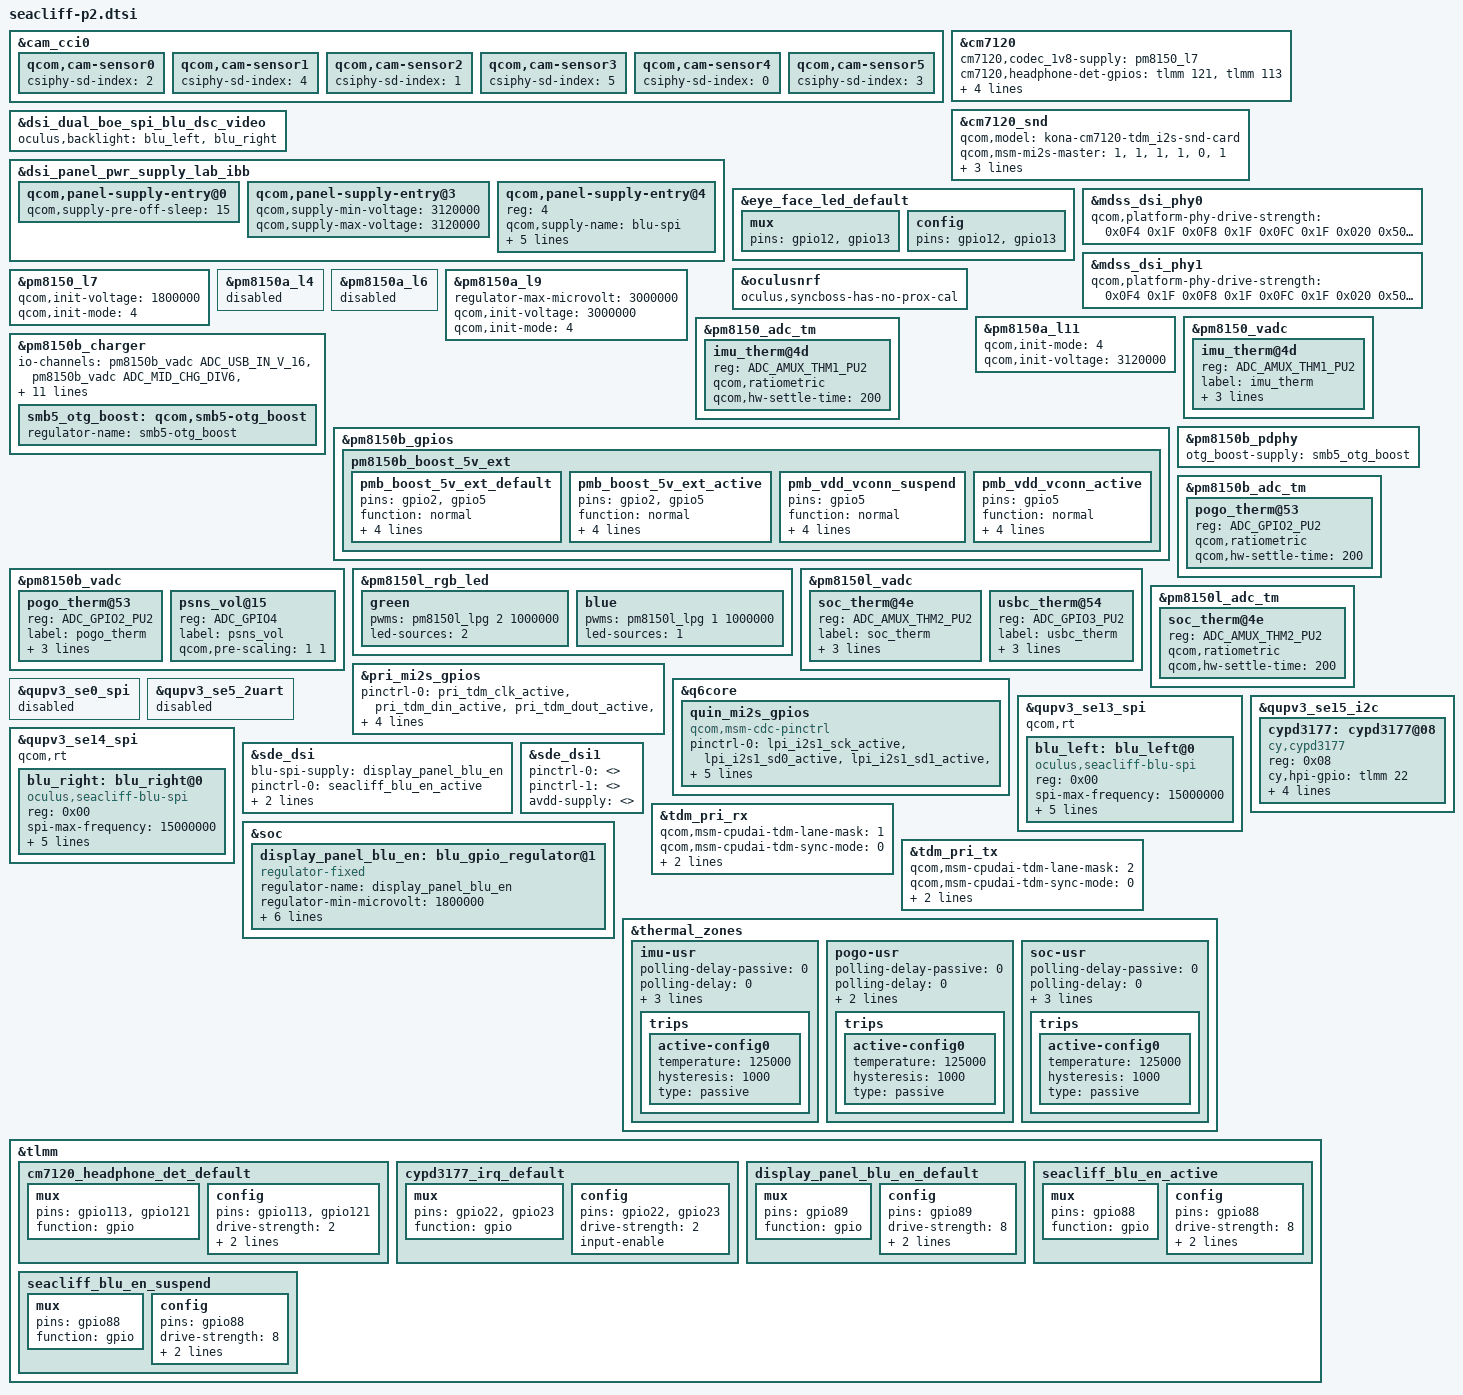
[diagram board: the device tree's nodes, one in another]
#include <dt-bindings/clock/qcom,gcc-kona.h>
#include <dt-bindings/clock/qcom,camcc-kona.h>
#include <dt-bindings/clock/qcom,rpmh.h>
#include <dt-bindings/interrupt-controller/arm-gic.h>

#include "seacliff-pop.dtsi"
#include "seacliff-bcmdhd.dtsi"
#include "seacliff-eye-face-led.dtsi"
#include "seacliff-safetyboss.dtsi"

&cam_cci0 {
	qcom,cam-sensor0 {
		csiphy-sd-index = <2>;
	};
	qcom,cam-sensor1 {
		csiphy-sd-index = <4>;
	};
	qcom,cam-sensor2 {
		csiphy-sd-index = <1>;
	};
	qcom,cam-sensor3 {
		csiphy-sd-index = <5>;
	};
	qcom,cam-sensor4 {
		csiphy-sd-index = <0>;
	};
	qcom,cam-sensor5 {
		csiphy-sd-index = <3>;
	};
};

&cm7120 {
	cm7120,codec_1v8-supply = <&pm8150_l7>;
	cm7120,headphone-det-gpios = <&tlmm 121 0
				   &tlmm 113 0>;
	cm7120,firmware-name = "CM7120_TDM_I2S.bin";
	pinctrl-0 = <&cm7120_codec_ldo_en_default
		&cm7120_codec_reset_default
		&cm7120_headphone_det_default>;
};

&cm7120_snd {
	qcom,model = "kona-cm7120-tdm_i2s-snd-card";
	qcom,msm-mi2s-master = <1>, <1>, <1>, <1>, <0>, <1>;
	qcom,quin-mi2s-gpios = <&quin_mi2s_gpios>;
	qcom,tdm-audio-intf = <1>;
	qcom,tdm-max-slots = <4>;
};

&dsi_dual_boe_spi_blu_dsc_video {
	oculus,backlight = <&blu_left &blu_right>;
};

&dsi_panel_pwr_supply_lab_ibb {
	qcom,panel-supply-entry@0 {
		qcom,supply-pre-off-sleep = <15>;
	};

	qcom,panel-supply-entry@3 {
		qcom,supply-min-voltage = <3120000>;
		qcom,supply-max-voltage = <3120000>;
	};

	qcom,panel-supply-entry@4 {
		reg = <4>;
		qcom,supply-name = "blu-spi";
		qcom,supply-min-voltage = <1800000>;
		qcom,supply-max-voltage = <1800000>;
		qcom,supply-enable-load = <62000>;
		qcom,supply-disable-load = <0>;
		qcom,supply-pre-on-sleep = <10>;
	};
};

&eye_face_led_default {
	mux {
		pins = "gpio12", "gpio13";
	};

	config {
		pins = "gpio12", "gpio13";
	};
};

&mdss_dsi_phy0 {
	qcom,platform-phy-drive-strength = <0x0F4 0x1F
		0x0F8 0x1F
		0x0FC 0x1F
		0x020 0x50
		0x110 0x55>;
};

&mdss_dsi_phy1 {
	qcom,platform-phy-drive-strength = <0x0F4 0x1F
		0x0F8 0x1F
		0x0FC 0x1F
		0x020 0x50
		0x110 0x55>;
};

&oculusnrf {
	oculus,syncboss-has-no-prox-cal;
};

&pm8150_l7 {
	qcom,init-voltage = <1800000>;
	qcom,init-mode = <4>; /* RPMH_REGULATOR_MODE_HPM */
};

&pm8150a_l4 {
	status = "disabled";
};

&pm8150a_l6 {
	status = "disabled";
};

&pm8150a_l9 {
	regulator-max-microvolt = <3000000>;
	qcom,init-voltage = <3000000>;
	qcom,init-mode = <4>; /* RPMH_REGULATOR_MODE_HPM */
};

&pm8150a_l11 {
	qcom,init-mode = <4>; /* RPMH_REGULATOR_MODE_HPM */
	qcom,init-voltage = <3120000>;
};

&pm8150_vadc {
	imu_therm@4d {
		reg = <ADC_AMUX_THM1_PU2>;
		label = "imu_therm";
		qcom,ratiometric;
		qcom,hw-settle-time = <200>;
		qcom,pre-scaling = <1 1>;
	};
};

&pm8150_adc_tm {
	imu_therm@4d {
		reg = <ADC_AMUX_THM1_PU2>;
		qcom,ratiometric;
		qcom,hw-settle-time = <200>;
	};
};

&pm8150b_charger {
	io-channels = <&pm8150b_vadc ADC_USB_IN_V_16>,
		      <&pm8150b_vadc ADC_MID_CHG_DIV6>,
		      <&pm8150b_vadc ADC_USB_IN_I>,
		      <&pm8150b_vadc ADC_SBUx>,
		      <&pm8150b_vadc ADC_VPH_PWR>,
		      <&pm8150b_vadc ADC_CHG_TEMP>,
		      <&pm8150b_vadc ADC_AMUX_THM3_PU2>,
		      <&pm8150b_vadc ADC_GPIO4>;
	io-channel-names = "usb_in_voltage",
			   "mid_voltage",
			   "usb_in_current",
			   "sbux_res",
			   "vph_voltage",
			   "chg_temp",
			   "rblt_res",
			   "psns_res";
	dcin-icl-uv = <40000>;

	pinctrl-names = "default", "boost_5v_active",
			"vdd_vconn_suspend", "vdd_vconn_active";
	pinctrl-0 = <&pmb_boost_5v_ext_default>;
	pinctrl-1 = <&pmb_boost_5v_ext_active>;
	pinctrl-2 = <&pmb_vdd_vconn_suspend>;
	pinctrl-3 = <&pmb_vdd_vconn_active>;

	smb5_otg_boost: qcom,smb5-otg_boost {
		regulator-name = "smb5-otg_boost";
	};
};

&pm8150b_gpios {
	pm8150b_boost_5v_ext {
		pmb_boost_5v_ext_default: pmb_boost_5v_ext_default {
			pins = "gpio2", "gpio5";
			function = "normal";
			input-disable;
			output-enable;
			output-low;
			power-source = <0>;
		};
		pmb_boost_5v_ext_active: pmb_boost_5v_ext_active {
			pins = "gpio2", "gpio5";
			function = "normal";
			input-disable;
			output-enable;
			output-high;
			power-source = <0>;
		};

		pmb_vdd_vconn_suspend: pmb_vdd_vconn_suspend {
			pins = "gpio5";
			function = "normal";
			input-disable;
			output-enable;
			output-low;
			power-source = <0>;
		};

		pmb_vdd_vconn_active: pmb_vdd_vconn_active {
			pins = "gpio5";
			function = "normal";
			input-disable;
			output-enable;
			output-high;
			power-source = <0>;
		};
	};
};

&pm8150b_pdphy {
	otg_boost-supply = <&smb5_otg_boost>;
};

&pm8150b_vadc {
	pogo_therm@53 {
		reg = <ADC_GPIO2_PU2>;
		label = "pogo_therm";
		qcom,ratiometric;
		qcom,hw-settle-time = <200>;
		qcom,pre-scaling = <1 1>;
	};

	psns_vol@15 {
		reg = <ADC_GPIO4>;
		label = "psns_vol";
		qcom,pre-scaling = <1 1>;
	};
};

&pm8150b_adc_tm {
	pogo_therm@53 {
		reg = <ADC_GPIO2_PU2>;
		qcom,ratiometric;
		qcom,hw-settle-time = <200>;
	};
};

&pm8150l_rgb_led {
	green {
		pwms = <&pm8150l_lpg 2 1000000>;
		led-sources = <2>;
	};

	blue {
		pwms = <&pm8150l_lpg 1 1000000>;
		led-sources = <1>;
	};
};

&pm8150l_vadc {
	soc_therm@4e {
		reg = <ADC_AMUX_THM2_PU2>;
		label = "soc_therm";
		qcom,ratiometric;
		qcom,hw-settle-time = <200>;
		qcom,pre-scaling = <1 1>;
	};

	usbc_therm@54 {
		reg = <ADC_GPIO3_PU2>;
		label = "usbc_therm";
		qcom,ratiometric;
		qcom,hw-settle-time = <200>;
		qcom,pre-scaling = <1 1>;
	};
};

&pm8150l_adc_tm {
	soc_therm@4e {
		reg = <ADC_AMUX_THM2_PU2>;
		qcom,ratiometric;
		qcom,hw-settle-time = <200>;
	};
};

&pri_mi2s_gpios {
	pinctrl-0 = <&pri_tdm_clk_active
		&pri_tdm_din_active
		&pri_tdm_dout_active
		&pri_tdm_sync_active>;
	pinctrl-1 = <&pri_tdm_clk_sleep
		&pri_tdm_din_sleep
		&pri_tdm_dout_sleep
		&pri_tdm_sync_sleep>;
};

&q6core {
	quin_mi2s_gpios: quin_mi2s_gpios {
		compatible = "qcom,msm-cdc-pinctrl";
		pinctrl-names = "aud_active", "aud_sleep";
		pinctrl-0 = <&lpi_i2s1_sck_active
			&lpi_i2s1_sd0_active
			&lpi_i2s1_sd1_active
			&lpi_i2s1_ws_active>;
		pinctrl-1 = <&lpi_i2s1_sck_sleep
			&lpi_i2s1_sd0_sleep
			&lpi_i2s1_sd1_sleep
			&lpi_i2s1_ws_sleep>;
		qcom,lpi-gpios;
	};
};

&qupv3_se0_spi {
	status = "disabled";
};

&qupv3_se5_2uart {
	status = "disabled";
};

&qupv3_se13_spi {
	status = "ok";
	qcom,rt;

	blu_left: blu_left@0 {
		compatible = "oculus,seacliff-blu-spi";
		reg = <0x00>;
		spi-max-frequency = <15000000>;
		oculus,blu-init-matrix = [21 04 80 07 00
			00 00 00 00 00 00 00 00 00 00 00 00 00 00 00 00 00 00 00 00 00 00 00 00
			00 00 00 00 1F FE 1F FE 1F FE 1F FE 1F FE 1F FE 1F FE 1F FE 1F FE 1F FE
			1F FE 1F FE 1F FE 1F FE 1F FE 1F FE 1F FE 1F FE 1F FE 1F FE 1F FE 1F FE
			1F FE 1F FE 1F FE 1F FE 1F FE 1F FE 1F FE 1F FE 1F FE 1F FE 1F FE 1F FE
			1F FE 1F FE 1F FE 1F FE 1F FE 1F FE 1F FE 1F FE 00 00 00 00 1F FE 1F FE
			00 00 00 00 00 00 00 00 00 00 00 00 00 00 00 00 00 00 00 00 00 00 00 00
			00 00 00 00 00 00 1F FE 00 00 1F FE 1F FE 1F FE 1F FE 1F FE 1F FE 1F FE
			1F FE 1F FE 1F FE 1F FE 1F FE 1F FE 1F FE 1F FE 1F FE 1F FE 1F FE 1F FE
			1F FE 1F FE 1F FE 1F FE 1F FE 1F FE 1F FE 1F FE 1F FE 1F FE 1F FE 1F FE
			1F FE 1F FE 1F FE 1F FE 1F FE 1F FE 1F FE 1F FE 1F FE 1F FE 1F FE 1F FE
			1F FE 1F FE 1F FE 1F FE 1F FE 1F FE 1F FE 1F FE 1F FE 1F FE 1F FE 1F FE
			1F FE 1F FE 1F FE 1F FE 00 00 1F FE 1F FE 1F FE 00 00 00 00 00 00 1F FE
			1F FE 1F FE 1F FE 1F FE 1F FE 1F FE 1F FE 1F FE 1F FE 1F FE 1F FE 1F FE
			1F FE 1F FE 1F FE 1F FE 1F FE 1F FE 1F FE 1F FE 1F FE 1F FE 1F FE 1F FE
			1F FE 1F FE 1F FE 1F FE 1F FE 1F FE 1F FE 1F FE 1F FE 1F FE 1F FE 1F FE
			1F FE 1F FE 1F FE 1F FE 1F FE 1F FE 1F FE 1F FE 1F FE 1F FE 1F FE 1F FE
			1F FE 1F FE 1F FE 1F FE 1F FE 1F FE 1F FE 1F FE 1F FE 1F FE 1F FE 1F FE
			1F FE 1F FE 1F FE 1F FE 1F FE 1F FE 1F FE 1F FE 1F FE 1F FE 1F FE 1F FE
			1F FE 1F FE 1F FE 1F FE 1F FE 1F FE 1F FE 1F FE 1F FE 1F FE 1F FE 1F FE
			1F FE 1F FE 1F FE 1F FE 1F FE 1F FE 1F FE 1F FE 1F FE 1F FE 1F FE 1F FE
			1F FE 1F FE 1F FE 1F FE 1F FE 1F FE 1F FE 1F FE 1F FE 1F FE 1F FE 1F FE
			1F FE 1F FE 1F FE 1F FE 1F FE 1F FE 1F FE 1F FE 1F FE 1F FE 1F FE 1F FE
			1F FE 1F FE 1F FE 1F FE 1F FE 1F FE 1F FE 1F FE 1F FE 1F FE 1F FE 1F FE
			1F FE 1F FE 1F FE 1F FE 1F FE 1F FE 1F FE 1F FE 1F FE 1F FE 1F FE 1F FE
			1F FE 1F FE 1F FE 1F FE 1F FE 1F FE 1F FE 1F FE 1F FE 1F FE 1F FE 1F FE
			1F FE 1F FE 1F FE 1F FE 1F FE 1F FE 1F FE 1F FE 1F FE 1F FE 1F FE 1F FE
			1F FE 1F FE 1F FE 1F FE 1F FE 1F FE 1F FE 1F FE 1F FE 1F FE 1F FE 1F FE
			1F FE 1F FE 1F FE 1F FE 1F FE 1F FE 1F FE 1F FE 1F FE 1F FE 1F FE 1F FE
			1F FE 1F FE 1F FE 1F FE 1F FE 1F FE 1F FE 1F FE 1F FE 1F FE 1F FE 1F FE
			1F FE 1F FE 1F FE 1F FE 1F FE 1F FE 1F FE 1F FE 1F FE 1F FE 1F FE 1F FE
			1F FE 1F FE 1F FE 1F FE 1F FE 1F FE 1F FE 1F FE 1F FE 1F FE 1F FE 1F FE
			1F FE 1F FE 1F FE 1F FE 1F FE 1F FE 1F FE 1F FE 1F FE 1F FE 1F FE 1F FE
			1F FE 1F FE 1F FE 1F FE 1F FE 1F FE 1F FE 1F FE 1F FE 1F FE 1F FE 1F FE
			1F FE 1F FE 1F FE 1F FE 1F FE 1F FE 1F FE 1F FE 1F FE 1F FE 1F FE 1F FE
			1F FE 1F FE 1F FE 1F FE 1F FE 1F FE 1F FE 1F FE 1F FE 1F FE 1F FE 1F FE
			1F FE 1F FE 1F FE 1F FE 1F FE 1F FE 1F FE 1F FE 1F FF 1F FE 1F FE 1F FE
			1F FE 00 00 00 00 00 00 1F FE 1F FE 1F FE 00 00 1F FE 1F FE 1F FE 1F FE
			1F FE 1F FE 1F FE 1F FE 1F FE 1F FE 1F FE 1F FE 1F FE 1F FE 1F FE 1F FE
			1F FE 1F FE 1F FE 1F FE 1F FE 1F FE 1F FE 1F FE 1F FE 1F FE 1F FE 1F FE
			1F FE 1F FE 1F FE 1F FE 1F FE 1F FE 1F FE 1F FE 1F FE 1F FE 1F FE 1F FE
			1F FE 1F FE 1F FE 1F FE 1F FE 1F FE 1F FE 1F FE 1F FE 1F FE 1F FE 1F FE
			1F FE 1F FE 1F FE 1F FE 1F FE 1F FE 1F FE 00 00 1F FE 00 00 00 00 00 00
			00 00 00 00 1F FE 1F FE 1F FE 1F FE 1F FE 1F FE 1F FE 1F FE 1F FE 1F FE
			1F FE 1F FE 1F FE 1F FE 1F FE 1F FE 1F FE 1F FE 1F FE 1F FE 1F FE 1F FE
			1F FE 1F FE 1F FE 1F FE 1F FE 1F FE 1F FE 1F FE 1F FE 1F FE 1F FE 1F FE
			1F FE 1F FE 1F FE 1F FE 1F FE 1F FE 1F FE 1F FE 1F FE 1F FE 1F FE 1F FE
			1F FE 1F FE 1F FE 1F FE 1F FE 1F FE 1F FE 1F FE 1F FE 1F FE 1F FE 1F FE
			1F FE 1F FE 1F FE 1F FE 1F FE 1F FE 1F FE 1F FE 1F FE 1F FE 1F FE 1F FE
			01
		];
		oculus,blu-irq-gpio = <&tlmm 111 0>;
		oculus,blu-name = "seacliff-left-blu";
		oculus,continuous-splash;
	};
};

&qupv3_se14_spi {
	status = "ok";
	qcom,rt;

	blu_right: blu_right@0 {
		compatible = "oculus,seacliff-blu-spi";
		reg = <0x00>;
		spi-max-frequency = <15000000>;
		oculus,blu-init-matrix = [21 04 80 07 00
			00 00 00 00 00 00 00 00 00 00 00 00 00 00 00 00 00 00 00 00 00 00 00 00
			00 00 00 00 1F FE 1F FE 1F FE 1F FE 1F FE 1F FE 1F FE 1F FE 1F FE 1F FE
			1F FE 1F FE 1F FE 1F FE 1F FE 1F FE 1F FE 1F FE 1F FE 1F FE 1F FE 1F FE
			1F FE 1F FE 1F FE 1F FE 1F FE 1F FE 1F FE 1F FE 1F FE 1F FE 1F FE 1F FE
			1F FE 1F FE 1F FE 1F FE 1F FE 1F FE 1F FE 1F FE 00 00 00 00 1F FE 1F FE
			00 00 00 00 00 00 00 00 00 00 00 00 00 00 00 00 00 00 00 00 00 00 00 00
			00 00 00 00 00 00 1F FE 00 00 1F FE 1F FE 1F FE 1F FE 1F FE 1F FE 1F FE
			1F FE 1F FE 1F FE 1F FE 1F FE 1F FE 1F FE 1F FE 1F FE 1F FE 1F FE 1F FE
			1F FE 1F FE 1F FE 1F FE 1F FE 1F FE 1F FE 1F FE 1F FE 1F FE 1F FE 1F FE
			1F FE 1F FE 1F FE 1F FE 1F FE 1F FE 1F FE 1F FE 1F FE 1F FE 1F FE 1F FE
			1F FE 1F FE 1F FE 1F FE 1F FE 1F FE 1F FE 1F FE 1F FE 1F FE 1F FE 1F FE
			1F FE 1F FE 1F FE 1F FE 00 00 1F FE 1F FE 1F FE 00 00 00 00 00 00 1F FE
			1F FE 1F FE 1F FE 1F FE 1F FE 1F FE 1F FE 1F FE 1F FE 1F FE 1F FE 1F FE
			1F FE 1F FE 1F FE 1F FE 1F FE 1F FE 1F FE 1F FE 1F FE 1F FE 1F FE 1F FE
			1F FE 1F FE 1F FE 1F FE 1F FE 1F FE 1F FE 1F FE 1F FE 1F FE 1F FE 1F FE
			1F FE 1F FE 1F FE 1F FE 1F FE 1F FE 1F FE 1F FE 1F FE 1F FE 1F FE 1F FE
			1F FE 1F FE 1F FE 1F FE 1F FE 1F FE 1F FE 1F FE 1F FE 1F FE 1F FE 1F FE
			1F FE 1F FE 1F FE 1F FE 1F FE 1F FE 1F FE 1F FE 1F FE 1F FE 1F FE 1F FE
			1F FE 1F FE 1F FE 1F FE 1F FE 1F FE 1F FE 1F FE 1F FE 1F FE 1F FE 1F FE
			1F FE 1F FE 1F FE 1F FE 1F FE 1F FE 1F FE 1F FE 1F FE 1F FE 1F FE 1F FE
			1F FE 1F FE 1F FE 1F FE 1F FE 1F FE 1F FE 1F FE 1F FE 1F FE 1F FE 1F FE
			1F FE 1F FE 1F FE 1F FE 1F FE 1F FE 1F FE 1F FE 1F FE 1F FE 1F FE 1F FE
			1F FE 1F FE 1F FE 1F FE 1F FE 1F FE 1F FE 1F FE 1F FE 1F FE 1F FE 1F FE
			1F FE 1F FE 1F FE 1F FE 1F FE 1F FE 1F FE 1F FE 1F FE 1F FE 1F FE 1F FE
			1F FE 1F FE 1F FE 1F FE 1F FE 1F FE 1F FE 1F FE 1F FE 1F FE 1F FE 1F FE
			1F FE 1F FE 1F FE 1F FE 1F FE 1F FE 1F FE 1F FE 1F FE 1F FE 1F FE 1F FE
			1F FE 1F FE 1F FE 1F FE 1F FE 1F FE 1F FE 1F FE 1F FE 1F FE 1F FE 1F FE
			1F FE 1F FE 1F FE 1F FE 1F FE 1F FE 1F FE 1F FE 1F FE 1F FE 1F FE 1F FE
			1F FE 1F FE 1F FE 1F FE 1F FE 1F FE 1F FE 1F FE 1F FE 1F FE 1F FE 1F FE
			1F FE 1F FE 1F FE 1F FE 1F FE 1F FE 1F FE 1F FE 1F FE 1F FE 1F FE 1F FE
			1F FE 1F FE 1F FE 1F FE 1F FE 1F FE 1F FE 1F FE 1F FE 1F FE 1F FE 1F FE
			1F FE 1F FE 1F FE 1F FE 1F FE 1F FE 1F FE 1F FE 1F FE 1F FE 1F FE 1F FE
			1F FE 1F FE 1F FE 1F FE 1F FE 1F FE 1F FE 1F FE 1F FE 1F FE 1F FE 1F FE
			1F FE 1F FE 1F FE 1F FE 1F FE 1F FE 1F FE 1F FE 1F FE 1F FE 1F FE 1F FE
			1F FE 1F FE 1F FE 1F FE 1F FE 1F FE 1F FE 1F FE 1F FE 1F FE 1F FE 1F FE
			1F FE 1F FE 1F FE 1F FE 1F FE 1F FE 1F FE 1F FE 1F FF 1F FE 1F FE 1F FE
			1F FE 00 00 00 00 00 00 1F FE 1F FE 1F FE 00 00 1F FE 1F FE 1F FE 1F FE
			1F FE 1F FE 1F FE 1F FE 1F FE 1F FE 1F FE 1F FE 1F FE 1F FE 1F FE 1F FE
			1F FE 1F FE 1F FE 1F FE 1F FE 1F FE 1F FE 1F FE 1F FE 1F FE 1F FE 1F FE
			1F FE 1F FE 1F FE 1F FE 1F FE 1F FE 1F FE 1F FE 1F FE 1F FE 1F FE 1F FE
			1F FE 1F FE 1F FE 1F FE 1F FE 1F FE 1F FE 1F FE 1F FE 1F FE 1F FE 1F FE
			1F FE 1F FE 1F FE 1F FE 1F FE 1F FE 1F FE 00 00 1F FE 00 00 00 00 00 00
			00 00 00 00 1F FE 1F FE 1F FE 1F FE 1F FE 1F FE 1F FE 1F FE 1F FE 1F FE
			1F FE 1F FE 1F FE 1F FE 1F FE 1F FE 1F FE 1F FE 1F FE 1F FE 1F FE 1F FE
			1F FE 1F FE 1F FE 1F FE 1F FE 1F FE 1F FE 1F FE 1F FE 1F FE 1F FE 1F FE
			1F FE 1F FE 1F FE 1F FE 1F FE 1F FE 1F FE 1F FE 1F FE 1F FE 1F FE 1F FE
			1F FE 1F FE 1F FE 1F FE 1F FE 1F FE 1F FE 1F FE 1F FE 1F FE 1F FE 1F FE
			1F FE 1F FE 1F FE 1F FE 1F FE 1F FE 1F FE 1F FE 1F FE 1F FE 1F FE 1F FE
			01
		];
		oculus,blu-irq-gpio = <&tlmm 112 0>;
		oculus,blu-name = "seacliff-right-blu";
		oculus,continuous-splash;
	};
};

&qupv3_se15_i2c {
	cypd3177: cypd3177@08 {
		compatible = "cy,cypd3177";
		reg = <0x08>;
		status = "ok";
		cy,hpi-gpio = <&tlmm 22 0x0>;
		cy,fault-gpio = <&tlmm 23 0x1>;
		interrupt-parent = <&tlmm>;
		interrupts = <13 2>, <14 1>;
		interrupt-names = "cypd3177_hpi_irq", "cypd3177_fault_irq";
		pinctrl-names = "default";
		pinctrl-0 = <&cypd3177_irq_default>;
	};
};

&sde_dsi {
	blu-spi-supply = <&display_panel_blu_en>;
	pinctrl-0 = <&seacliff_blu_en_active>;
	pinctrl-1 = <&seacliff_blu_en_suspend>;
	avdd-supply = <>;
};

&sde_dsi1 {
	pinctrl-0 = <>;
	pinctrl-1 = <>;
	avdd-supply = <>;
};

&soc {
	display_panel_blu_en: blu_gpio_regulator@1 {
		compatible = "regulator-fixed";
		regulator-name = "display_panel_blu_en";
		regulator-min-microvolt = <1800000>;
		regulator-max-microvolt = <1800000>;
		regulator-enable-ramp-delay = <233>;
		gpio = <&tlmm 89 0>;
		enable-active-high;
		regulator-boot-on;
		pinctrl-names = "default";
		pinctrl-0 = <&display_panel_blu_en_default>;
	};
};

&tdm_pri_rx {
	qcom,msm-cpudai-tdm-lane-mask = /bits/ 16 <1>;
	qcom,msm-cpudai-tdm-sync-mode = <0>;
	qcom,msm-cpudai-tdm-invert-sync = <0>;
	qcom,msm-cpudai-tdm-data-delay = <0>;
};

&tdm_pri_tx {
	qcom,msm-cpudai-tdm-lane-mask = /bits/ 16 <2>;
	qcom,msm-cpudai-tdm-sync-mode = <0>;
	qcom,msm-cpudai-tdm-invert-sync = <0>;
	qcom,msm-cpudai-tdm-data-delay = <0>;
};

&thermal_zones {
	imu-usr {
		polling-delay-passive = <0>;
		polling-delay = <0>;
		thermal-governor = "user_space";
		thermal-sensors = <&pm8150_adc_tm ADC_AMUX_THM1_PU2>;
		trips {
			active-config0 {
				temperature = <125000>;
				hysteresis = <1000>;
				type = "passive";
			};
		};
	};

	pogo-usr {
		polling-delay-passive = <0>;
		polling-delay = <0>;
		thermal-governor = "user_space";
		thermal-sensors = <&pm8150b_adc_tm ADC_GPIO2_PU2>;
		trips {
			active-config0 {
				temperature = <125000>;
				hysteresis = <1000>;
				type = "passive";
			};
		};
	};

	soc-usr {
		polling-delay-passive = <0>;
		polling-delay = <0>;
		thermal-governor = "user_space";
		thermal-sensors = <&pm8150l_adc_tm ADC_AMUX_THM2_PU2>;
		trips {
			active-config0 {
				temperature = <125000>;
				hysteresis = <1000>;
				type = "passive";
			};
		};
	};
};

&tlmm {
	cm7120_headphone_det_default: cm7120_headphone_det_default {
		mux {
			pins = "gpio113", "gpio121";
			function = "gpio";
		};

		config {
			pins = "gpio113", "gpio121";
			drive-strength = <2>;
			input-enable;
			bias-disable;
		};
	};

	cypd3177_irq_default: cypd3177_irq_default {
		mux {
			pins = "gpio22", "gpio23";
			function = "gpio";
		};
		config {
			pins = "gpio22", "gpio23";
			drive-strength = <2>;
			input-enable;
		};
	};

	display_panel_blu_en_default: display_panel_blu_en_default {
		mux {
			pins = "gpio89";
			function = "gpio";
		};

		config {
			pins = "gpio89";
			drive-strength = <8>;
			bias-disable = <0>;
			output-high;
		};
	};

	seacliff_blu_en_active: seacliff_blu_en_active {
		mux {
			pins = "gpio88";
			function = "gpio";
		};

		config {
			pins = "gpio88";
			drive-strength = <8>;
			output-high;
			bias-pull-up;
		};
	};

	seacliff_blu_en_suspend: seacliff_blu_en_suspend {
		mux {
			pins = "gpio88";
			function = "gpio";
		};

		config {
			pins = "gpio88";
			drive-strength = <8>;
			output-low;
			bias-pull-down;
		};
	};
};
